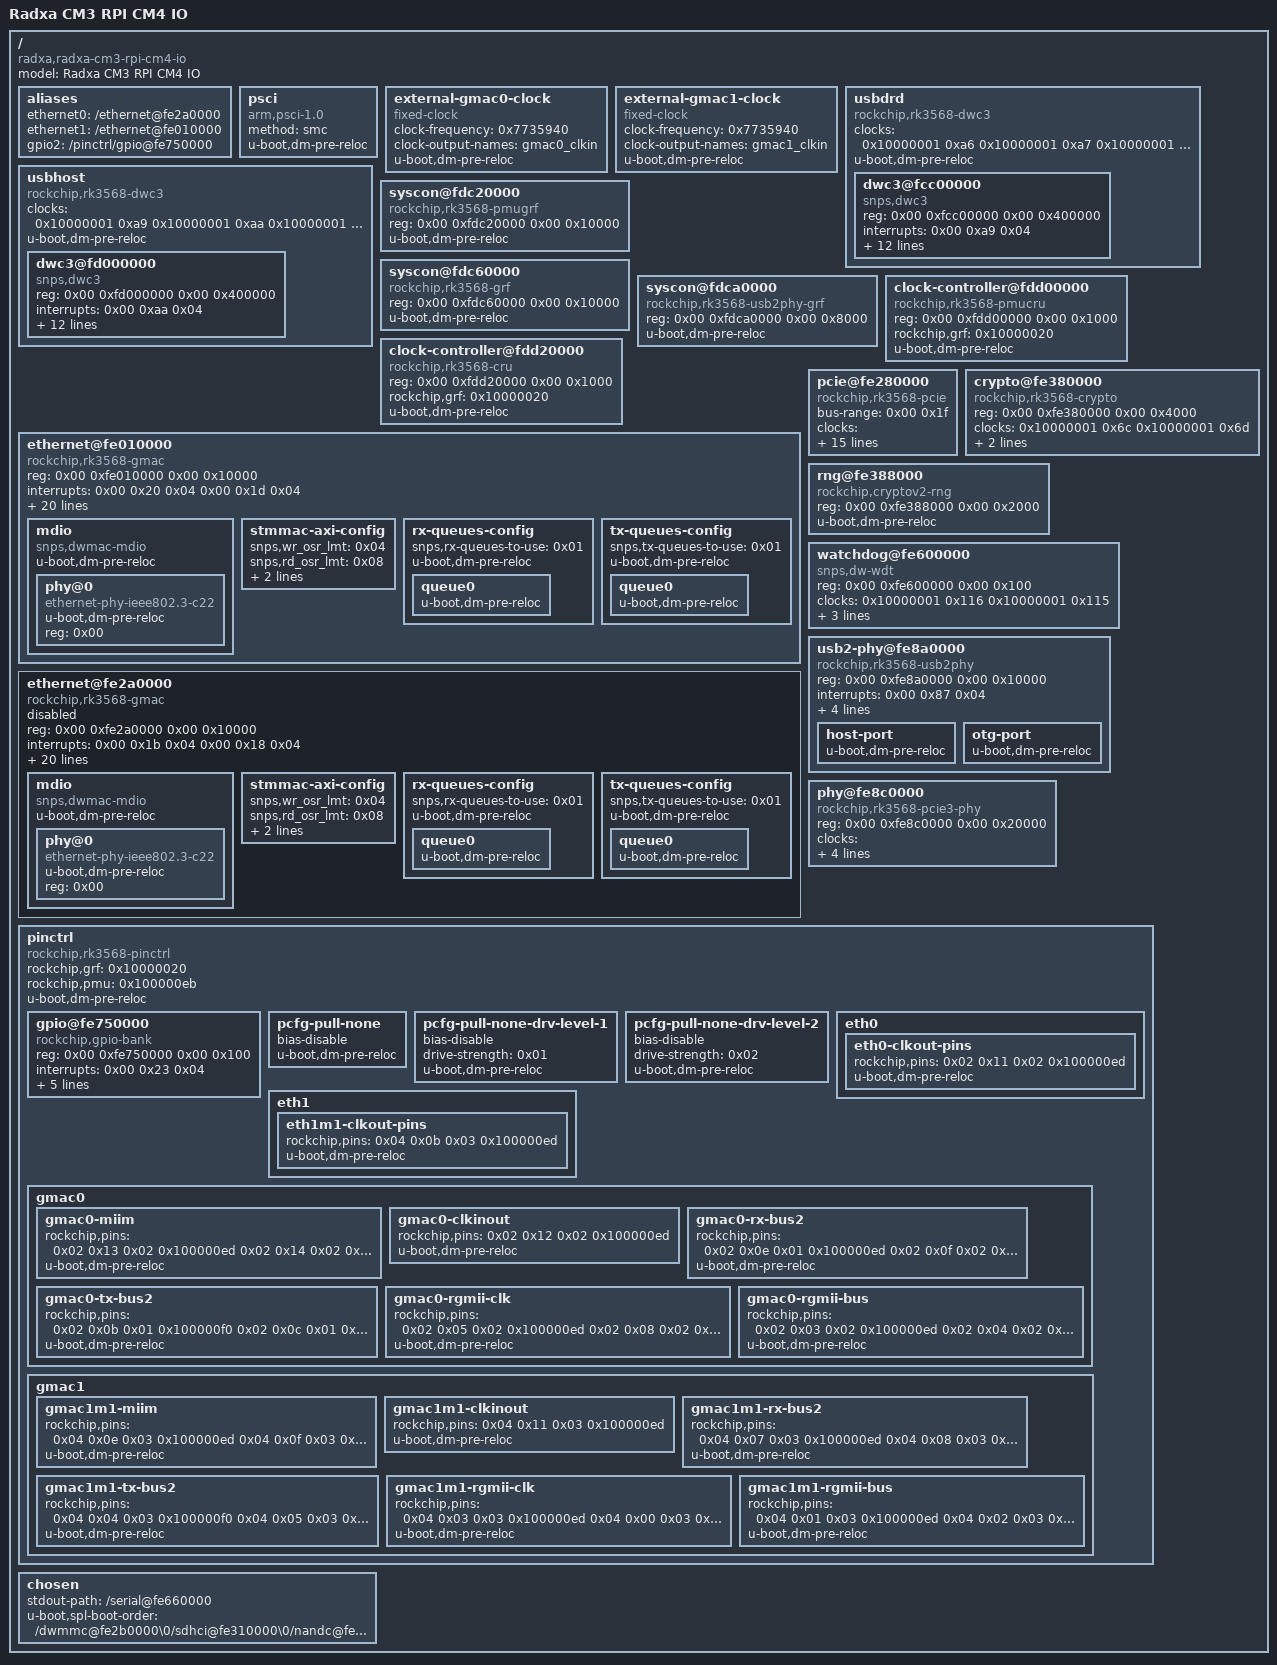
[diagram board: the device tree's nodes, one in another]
/dts-v1/;

/ {
	compatible = "radxa,radxa-cm3-rpi-cm4-io\0rockchip,rk3566";
	#address-cells = <0x02>;
	#size-cells = <0x02>;
	model = "Radxa CM3 RPI CM4 IO";

	aliases {
		ethernet0 = "/ethernet@fe2a0000";
		ethernet1 = "/ethernet@fe010000";
		gpio2 = "/pinctrl/gpio@fe750000";
	};

	psci {
		compatible = "arm,psci-1.0";
		method = "smc";
		u-boot,dm-pre-reloc;
		status = "okay";
	};

	external-gmac0-clock {
		compatible = "fixed-clock";
		clock-frequency = <0x7735940>;
		clock-output-names = "gmac0_clkin";
		#clock-cells = <0x00>;
		u-boot,dm-pre-reloc;
	};

	external-gmac1-clock {
		compatible = "fixed-clock";
		clock-frequency = <0x7735940>;
		clock-output-names = "gmac1_clkin";
		#clock-cells = <0x00>;
		u-boot,dm-pre-reloc;
	};

	usbdrd {
		compatible = "rockchip,rk3568-dwc3\0rockchip,rk3399-dwc3";
		clocks = <0x10000001 0xa6 0x10000001 0xa7 0x10000001 0xa5>;
		#address-cells = <0x02>;
		#size-cells = <0x02>;
		ranges;
		status = "okay";
		u-boot,dm-pre-reloc;

		dwc3@fcc00000 {
			compatible = "snps,dwc3";
			reg = <0x00 0xfcc00000 0x00 0x400000>;
			interrupts = <0x00 0xa9 0x04>;
			dr_mode = "otg";
			phys = <0x1000000d>;
			phy-names = "usb2-phy";
			phy_type = "utmi_wide";
			power-domains = <0x1000000a 0x0f>;
			resets = <0x10000001 0x94>;
			reset-names = "usb3-otg";
			snps,dis_enblslpm_quirk;
			snps,dis-u2-freeclk-exists-quirk;
			snps,dis_u2_susphy_quirk;
			snps,dis-del-phy-power-chg-quirk;
			snps,dis-tx-ipgap-linecheck-quirk;
			snps,xhci-trb-ent-quirk;
			status = "okay";
			u-boot,dm-pre-reloc;
		};
	};

	usbhost {
		compatible = "rockchip,rk3568-dwc3\0rockchip,rk3399-dwc3";
		clocks = <0x10000001 0xa9 0x10000001 0xaa 0x10000001 0xa8>;
		#address-cells = <0x02>;
		#size-cells = <0x02>;
		ranges;
		status = "okay";
		u-boot,dm-pre-reloc;

		dwc3@fd000000 {
			compatible = "snps,dwc3";
			reg = <0x00 0xfd000000 0x00 0x400000>;
			interrupts = <0x00 0xaa 0x04>;
			dr_mode = "host";
			phys = <0x1000000e>;
			phy-names = "usb2-phy";
			phy_type = "utmi_wide";
			power-domains = <0x1000000a 0x0f>;
			resets = <0x10000001 0x95>;
			reset-names = "usb3-host";
			snps,dis_enblslpm_quirk;
			snps,dis-u2-freeclk-exists-quirk;
			snps,dis_u2_susphy_quirk;
			snps,dis-del-phy-power-chg-quirk;
			snps,dis-tx-ipgap-linecheck-quirk;
			snps,xhci-trb-ent-quirk;
			status = "okay";
			u-boot,dm-pre-reloc;
		};
	};

	syscon@fdc20000 {
		compatible = "rockchip,rk3568-pmugrf\0syscon\0simple-mfd";
		reg = <0x00 0xfdc20000 0x00 0x10000>;
		u-boot,dm-pre-reloc;
		status = "okay";
		phandle = <0x100000eb>;
	};

	syscon@fdc60000 {
		compatible = "rockchip,rk3568-grf\0syscon\0simple-mfd";
		reg = <0x00 0xfdc60000 0x00 0x10000>;
		u-boot,dm-pre-reloc;
		status = "okay";
		phandle = <0x10000020>;
	};

	syscon@fdca0000 {
		compatible = "rockchip,rk3568-usb2phy-grf\0syscon";
		reg = <0x00 0xfdca0000 0x00 0x8000>;
		u-boot,dm-pre-reloc;
		status = "okay";
		phandle = <0x100000e8>;
	};

	clock-controller@fdd00000 {
		compatible = "rockchip,rk3568-pmucru";
		reg = <0x00 0xfdd00000 0x00 0x1000>;
		rockchip,grf = <0x10000020>;
		#clock-cells = <0x01>;
		#reset-cells = <0x01>;
		u-boot,dm-pre-reloc;
		status = "okay";
		phandle = <0x1000001f>;
	};

	clock-controller@fdd20000 {
		compatible = "rockchip,rk3568-cru";
		reg = <0x00 0xfdd20000 0x00 0x1000>;
		rockchip,grf = <0x10000020>;
		#clock-cells = <0x01>;
		#reset-cells = <0x01>;
		u-boot,dm-pre-reloc;
		status = "okay";
		phandle = <0x10000001>;
	};

	ethernet@fe010000 {
		compatible = "rockchip,rk3568-gmac\0snps,dwmac-4.20a";
		reg = <0x00 0xfe010000 0x00 0x10000>;
		interrupts = <0x00 0x20 0x04 0x00 0x1d 0x04>;
		interrupt-names = "macirq\0eth_wake_irq";
		rockchip,grf = <0x10000020>;
		clocks = <0x10000001 0x186 0x10000001 0x189 0x10000001 0x189 0x10000001 0xc7 0x10000001 0xc3 0x10000001 0xc4 0x10000001 0x189 0x10000001 0xc8>;
		resets = <0x10000001 0xec>;
		reset-names = "stmmaceth";
		snps,mixed-burst;
		snps,tso;
		snps,axi-config = <0x1000005d>;
		snps,mtl-rx-config = <0x1000005e>;
		snps,mtl-tx-config = <0x1000005f>;
		status = "okay";
		u-boot,dm-pre-reloc;
		phy-mode = "rgmii";
		clock_in_out = "input";
		snps,reset-gpio = <0x10000060 0x12 0x01>;
		snps,reset-active-low;
		snps,reset-delays-us = <0x00 0x4e20 0x186a0>;
		pinctrl-names = "default";
		pinctrl-0 = <0x10000061 0x10000062 0x10000063 0x10000064 0x10000065>;
		tx_delay = <0x4f>;
		rx_delay = <0x26>;
		phy-handle = <0x10000066>;

		mdio {
			compatible = "snps,dwmac-mdio";
			#address-cells = <0x01>;
			#size-cells = <0x00>;
			u-boot,dm-pre-reloc;

			phy@0 {
				compatible = "ethernet-phy-ieee802.3-c22";
				u-boot,dm-pre-reloc;
				reg = <0x00>;
				phandle = <0x10000066>;
			};
		};

		stmmac-axi-config {
			snps,wr_osr_lmt = <0x04>;
			snps,rd_osr_lmt = <0x08>;
			snps,blen = <0x00 0x00 0x00 0x00 0x10 0x08 0x04>;
			u-boot,dm-pre-reloc;
			phandle = <0x1000005d>;
		};

		rx-queues-config {
			snps,rx-queues-to-use = <0x01>;
			u-boot,dm-pre-reloc;
			phandle = <0x1000005e>;

			queue0 {
				u-boot,dm-pre-reloc;
			};
		};

		tx-queues-config {
			snps,tx-queues-to-use = <0x01>;
			u-boot,dm-pre-reloc;
			phandle = <0x1000005f>;

			queue0 {
				u-boot,dm-pre-reloc;
			};
		};
	};

	pcie@fe280000 {
		compatible = "rockchip,rk3568-pcie\0snps,dw-pcie";
		#address-cells = <0x03>;
		#size-cells = <0x02>;
		bus-range = <0x00 0x1f>;
		clocks = <0x10000001 0x8f 0x10000001 0x90 0x10000001 0x91 0x10000001 0x92>;
		device_type = "pci";
		interrupts = <0x00 0xa5 0x04 0x00 0xa4 0x04 0x00 0xa3 0x04 0x00 0xa2 0x04 0x00 0xa1 0x04>;
		interrupt-names = "sys\0pmc\0msg\0legacy\0err";
		linux,pci-domain = <0x02>;
		num-ib-windows = <0x06>;
		num-ob-windows = <0x02>;
		max-link-speed = <0x03>;
		msi-map = <0x00 0x10000083 0x2000 0x1000>;
		num-lanes = <0x02>;
		phys = <0x10000084>;
		phy-names = "pcie-phy";
		power-domains = <0x1000000a 0x0f>;
		ranges = <0x800 0x00 0x80000000 0x03 0x80000000 0x00 0x800000 0x81000000 0x00 0x80800000 0x03 0x80800000 0x00 0x100000 0x83000000 0x00 0x80900000 0x03 0x80900000 0x00 0x3f700000>;
		reg = <0x03 0xc0800000 0x00 0x400000 0x00 0xfe280000 0x00 0x10000>;
		reg-names = "pcie-dbi\0pcie-apb";
		resets = <0x10000001 0xc1>;
		reset-names = "pipe";
		status = "okay";
		u-boot,dm-pre-reloc;
	};

	ethernet@fe2a0000 {
		compatible = "rockchip,rk3568-gmac\0snps,dwmac-4.20a";
		reg = <0x00 0xfe2a0000 0x00 0x10000>;
		interrupts = <0x00 0x1b 0x04 0x00 0x18 0x04>;
		interrupt-names = "macirq\0eth_wake_irq";
		rockchip,grf = <0x10000020>;
		clocks = <0x10000001 0x182 0x10000001 0x185 0x10000001 0x185 0x10000001 0xb8 0x10000001 0xb4 0x10000001 0xb5 0x10000001 0x185 0x10000001 0xb9>;
		resets = <0x10000001 0xd7>;
		reset-names = "stmmaceth";
		snps,mixed-burst;
		snps,tso;
		snps,axi-config = <0x10000085>;
		snps,mtl-rx-config = <0x10000086>;
		snps,mtl-tx-config = <0x10000087>;
		status = "disabled";
		u-boot,dm-pre-reloc;
		phy-mode = "rgmii";
		clock_in_out = "input";
		snps,reset-gpio = <0x10000060 0x12 0x01>;
		snps,reset-active-low;
		snps,reset-delays-us = <0x00 0x4e20 0x186a0>;
		pinctrl-names = "default";
		pinctrl-0 = <0x10000088 0x10000089 0x1000008a 0x1000008b 0x1000008c>;
		tx_delay = <0x4f>;
		rx_delay = <0x26>;
		phy-handle = <0x1000008d>;

		mdio {
			compatible = "snps,dwmac-mdio";
			#address-cells = <0x01>;
			#size-cells = <0x00>;
			u-boot,dm-pre-reloc;

			phy@0 {
				compatible = "ethernet-phy-ieee802.3-c22";
				u-boot,dm-pre-reloc;
				reg = <0x00>;
				phandle = <0x1000008d>;
			};
		};

		stmmac-axi-config {
			snps,wr_osr_lmt = <0x04>;
			snps,rd_osr_lmt = <0x08>;
			snps,blen = <0x00 0x00 0x00 0x00 0x10 0x08 0x04>;
			u-boot,dm-pre-reloc;
			phandle = <0x10000085>;
		};

		rx-queues-config {
			snps,rx-queues-to-use = <0x01>;
			u-boot,dm-pre-reloc;
			phandle = <0x10000086>;

			queue0 {
				u-boot,dm-pre-reloc;
			};
		};

		tx-queues-config {
			snps,tx-queues-to-use = <0x01>;
			u-boot,dm-pre-reloc;
			phandle = <0x10000087>;

			queue0 {
				u-boot,dm-pre-reloc;
			};
		};
	};

	crypto@fe380000 {
		compatible = "rockchip,rk3568-crypto";
		reg = <0x00 0xfe380000 0x00 0x4000>;
		clocks = <0x10000001 0x6c 0x10000001 0x6d>;
		clock-frequency = <0x8f0d180 0x11e1a300>;
		status = "okay";
		u-boot,dm-pre-reloc;
	};

	rng@fe388000 {
		compatible = "rockchip,cryptov2-rng";
		reg = <0x00 0xfe388000 0x00 0x2000>;
		status = "okay";
		u-boot,dm-pre-reloc;
	};

	watchdog@fe600000 {
		compatible = "snps,dw-wdt";
		reg = <0x00 0xfe600000 0x00 0x100>;
		clocks = <0x10000001 0x116 0x10000001 0x115>;
		interrupts = <0x00 0x95 0x04>;
		resets = <0x10000001 0x1a6>;
		reset-names = "reset";
		status = "okay";
		u-boot,dm-pre-reloc;
	};

	usb2-phy@fe8a0000 {
		compatible = "rockchip,rk3568-usb2phy";
		reg = <0x00 0xfe8a0000 0x00 0x10000>;
		interrupts = <0x00 0x87 0x04>;
		clocks = <0x1000001f 0x13>;
		#clock-cells = <0x00>;
		clock-output-names = "usb480m_phy";
		rockchip,usbgrf = <0x100000e8>;
		status = "okay";
		u-boot,dm-pre-reloc;
		phandle = <0x1000002c>;

		host-port {
			#phy-cells = <0x00>;
			status = "okay";
			u-boot,dm-pre-reloc;
			phandle = <0x1000000e>;
		};

		otg-port {
			#phy-cells = <0x00>;
			status = "okay";
			u-boot,dm-pre-reloc;
			phandle = <0x1000000d>;
		};
	};

	phy@fe8c0000 {
		compatible = "rockchip,rk3568-pcie3-phy";
		reg = <0x00 0xfe8c0000 0x00 0x20000>;
		#phy-cells = <0x00>;
		clocks = <0x1000001f 0x26 0x1000001f 0x27 0x10000001 0x177>;
		resets = <0x10000001 0x1be>;
		reset-names = "phy";
		rockchip,phy-grf = <0x100000ea>;
		status = "okay";
		u-boot,dm-pre-reloc;
		phandle = <0x10000084>;
	};

	pinctrl {
		compatible = "rockchip,rk3568-pinctrl";
		rockchip,grf = <0x10000020>;
		rockchip,pmu = <0x100000eb>;
		#address-cells = <0x02>;
		#size-cells = <0x02>;
		ranges;
		u-boot,dm-pre-reloc;
		status = "okay";
		phandle = <0x100000ec>;

		gpio@fe750000 {
			compatible = "rockchip,gpio-bank";
			reg = <0x00 0xfe750000 0x00 0x100>;
			interrupts = <0x00 0x23 0x04>;
			clocks = <0x10000001 0x165 0x10000001 0x166>;
			gpio-controller;
			#gpio-cells = <0x02>;
			gpio-ranges = <0x100000ec 0x00 0x40 0x20>;
			interrupt-controller;
			#interrupt-cells = <0x02>;
			u-boot,dm-pre-reloc;
		};

		pcfg-pull-none {
			bias-disable;
			u-boot,dm-pre-reloc;
			phandle = <0x100000ed>;
		};

		pcfg-pull-none-drv-level-1 {
			bias-disable;
			drive-strength = <0x01>;
			u-boot,dm-pre-reloc;
			phandle = <0x100000f1>;
		};

		pcfg-pull-none-drv-level-2 {
			bias-disable;
			drive-strength = <0x02>;
			u-boot,dm-pre-reloc;
			phandle = <0x100000f0>;
		};

		eth0 {

			eth0-clkout-pins {
				rockchip,pins = <0x02 0x11 0x02 0x100000ed>;
				u-boot,dm-pre-reloc;
			};
		};

		eth1 {

			eth1m1-clkout-pins {
				rockchip,pins = <0x04 0x0b 0x03 0x100000ed>;
				u-boot,dm-pre-reloc;
			};
		};

		gmac0 {

			gmac0-miim {
				rockchip,pins = <0x02 0x13 0x02 0x100000ed 0x02 0x14 0x02 0x100000ed>;
				u-boot,dm-pre-reloc;
				phandle = <0x10000088>;
			};

			gmac0-clkinout {
				rockchip,pins = <0x02 0x12 0x02 0x100000ed>;
				u-boot,dm-pre-reloc;
			};

			gmac0-rx-bus2 {
				rockchip,pins = <0x02 0x0e 0x01 0x100000ed 0x02 0x0f 0x02 0x100000ed 0x02 0x10 0x02 0x100000ed>;
				u-boot,dm-pre-reloc;
				phandle = <0x1000008a>;
			};

			gmac0-tx-bus2 {
				rockchip,pins = <0x02 0x0b 0x01 0x100000f0 0x02 0x0c 0x01 0x100000f0 0x02 0x0d 0x01 0x100000ed>;
				u-boot,dm-pre-reloc;
				phandle = <0x10000089>;
			};

			gmac0-rgmii-clk {
				rockchip,pins = <0x02 0x05 0x02 0x100000ed 0x02 0x08 0x02 0x100000f1>;
				u-boot,dm-pre-reloc;
				phandle = <0x1000008b>;
			};

			gmac0-rgmii-bus {
				rockchip,pins = <0x02 0x03 0x02 0x100000ed 0x02 0x04 0x02 0x100000ed 0x02 0x06 0x02 0x100000f0 0x02 0x07 0x02 0x100000f0>;
				u-boot,dm-pre-reloc;
				phandle = <0x1000008c>;
			};
		};

		gmac1 {

			gmac1m1-miim {
				rockchip,pins = <0x04 0x0e 0x03 0x100000ed 0x04 0x0f 0x03 0x100000ed>;
				u-boot,dm-pre-reloc;
				phandle = <0x10000061>;
			};

			gmac1m1-clkinout {
				rockchip,pins = <0x04 0x11 0x03 0x100000ed>;
				u-boot,dm-pre-reloc;
			};

			gmac1m1-rx-bus2 {
				rockchip,pins = <0x04 0x07 0x03 0x100000ed 0x04 0x08 0x03 0x100000ed 0x04 0x09 0x03 0x100000ed>;
				u-boot,dm-pre-reloc;
				phandle = <0x10000063>;
			};

			gmac1m1-tx-bus2 {
				rockchip,pins = <0x04 0x04 0x03 0x100000f0 0x04 0x05 0x03 0x100000f0 0x04 0x06 0x03 0x100000ed>;
				u-boot,dm-pre-reloc;
				phandle = <0x10000062>;
			};

			gmac1m1-rgmii-clk {
				rockchip,pins = <0x04 0x03 0x03 0x100000ed 0x04 0x00 0x03 0x100000f1>;
				u-boot,dm-pre-reloc;
				phandle = <0x10000064>;
			};

			gmac1m1-rgmii-bus {
				rockchip,pins = <0x04 0x01 0x03 0x100000ed 0x04 0x02 0x03 0x100000ed 0x03 0x1e 0x03 0x100000f0 0x03 0x1f 0x03 0x100000f0>;
				u-boot,dm-pre-reloc;
				phandle = <0x10000065>;
			};
		};
	};

	chosen {
		stdout-path = "/serial@fe660000";
		u-boot,spl-boot-order = "/dwmmc@fe2b0000\0/sdhci@fe310000\0/nandc@fe330000\0/sfc@fe300000/flash@0\0/sfc@fe300000/flash@1";
	};
};
